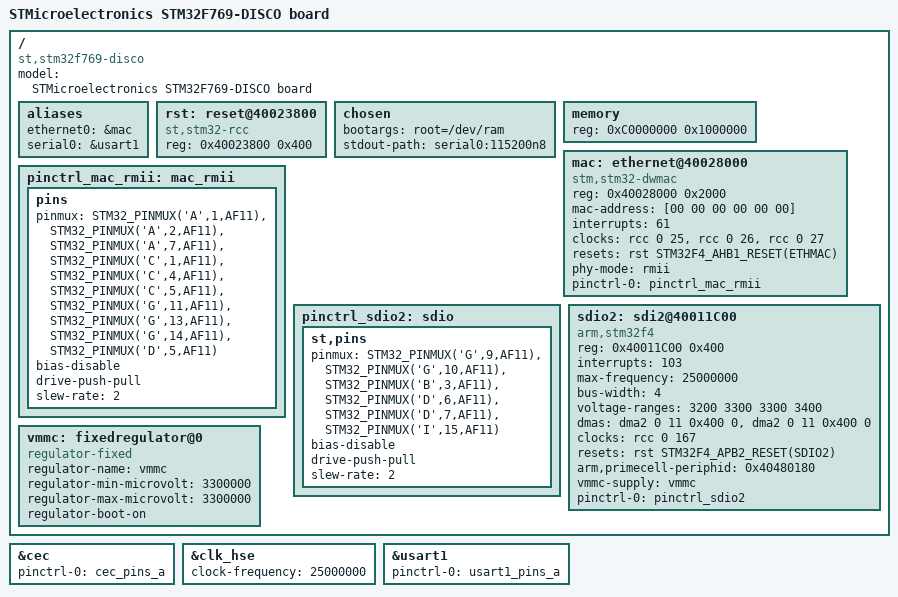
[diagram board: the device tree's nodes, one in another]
/*
 * Copyright 2017 - Vikas MANOCHA <vikas.manocha@st.com>
 *
 * This file is dual-licensed: you can use it either under the terms
 * of the GPL or the X11 license, at your option. Note that this dual
 * licensing only applies to this file, and not this project as a
 * whole.
 *
 *  a) This file is free software; you can redistribute it and/or
 *     modify it under the terms of the GNU General Public License as
 *     published by the Free Software Foundation; either version 2 of the
 *     License, or (at your option) any later version.
 *
 *     This file is distributed in the hope that it will be useful,
 *     but WITHOUT ANY WARRANTY; without even the implied warranty of
 *     MERCHANTABILITY or FITNESS FOR A PARTICULAR PURPOSE.  See the
 *     GNU General Public License for more details.
 *
 * Or, alternatively,
 *
 *  b) Permission is hereby granted, free of charge, to any person
 *     obtaining a copy of this software and associated documentation
 *     files (the "Software"), to deal in the Software without
 *     restriction, including without limitation the rights to use,
 *     copy, modify, merge, publish, distribute, sublicense, and/or
 *     sell copies of the Software, and to permit persons to whom the
 *     Software is furnished to do so, subject to the following
 *     conditions:
 *
 *     The above copyright notice and this permission notice shall be
 *     included in all copies or substantial portions of the Software.
 *
 *     THE SOFTWARE IS PROVIDED "AS IS", WITHOUT WARRANTY OF ANY KIND,
 *     EXPRESS OR IMPLIED, INCLUDING BUT NOT LIMITED TO THE WARRANTIES
 *     OF MERCHANTABILITY, FITNESS FOR A PARTICULAR PURPOSE AND
 *     NONINFRINGEMENT. IN NO EVENT SHALL THE AUTHORS OR COPYRIGHT
 *     HOLDERS BE LIABLE FOR ANY CLAIM, DAMAGES OR OTHER LIABILITY,
 *     WHETHER IN AN ACTION OF CONTRACT, TORT OR OTHERWISE, ARISING
 *     FROM, OUT OF OR IN CONNECTION WITH THE SOFTWARE OR THE USE OR
 *     OTHER DEALINGS IN THE SOFTWARE.
 */
 
 /* AHB1 */
#define STM32F4_RCC_AHB1_GPIOA	0
#define STM32F4_RCC_AHB1_GPIOB	1
#define STM32F4_RCC_AHB1_GPIOC	2
#define STM32F4_RCC_AHB1_GPIOD	3
#define STM32F4_RCC_AHB1_GPIOE	4
#define STM32F4_RCC_AHB1_GPIOF	5
#define STM32F4_RCC_AHB1_GPIOG	6
#define STM32F4_RCC_AHB1_GPIOH	7
#define STM32F4_RCC_AHB1_GPIOI	8
#define STM32F4_RCC_AHB1_GPIOJ	9
#define STM32F4_RCC_AHB1_GPIOK	10
#define STM32F4_RCC_AHB1_CRC	12
#define STM32F4_RCC_AHB1_DMA1	21
#define STM32F4_RCC_AHB1_DMA2	22
#define STM32F4_RCC_AHB1_DMA2D	23
#define STM32F4_RCC_AHB1_ETHMAC	25
#define STM32F4_RCC_AHB1_OTGHS	29

#define STM32F4_AHB1_RESET(bit) (STM32F4_RCC_AHB1_##bit + (0x10 * 8))

/* AHB2 */
#define STM32F4_RCC_AHB2_DCMI	0
#define STM32F4_RCC_AHB2_CRYP	4
#define STM32F4_RCC_AHB2_HASH	5
#define STM32F4_RCC_AHB2_RNG	6
#define STM32F4_RCC_AHB2_OTGFS	7

#define STM32F4_AHB2_RESET(bit)	(STM32F4_RCC_AHB2_##bit + (0x14 * 8))

/* AHB3 */
#define STM32F4_RCC_AHB3_FMC	0
#define STM32F4_RCC_AHB3_QSPI	1

#define STM32F4_AHB3_RESET(bit)	(STM32F4_RCC_AHB3_##bit + (0x18 * 8))

/* APB1 */
#define STM32F4_RCC_APB1_TIM2	0
#define STM32F4_RCC_APB1_TIM3	1
#define STM32F4_RCC_APB1_TIM4	2
#define STM32F4_RCC_APB1_TIM5	3
#define STM32F4_RCC_APB1_TIM6	4
#define STM32F4_RCC_APB1_TIM7	5
#define STM32F4_RCC_APB1_TIM12	6
#define STM32F4_RCC_APB1_TIM13	7
#define STM32F4_RCC_APB1_TIM14	8
#define STM32F4_RCC_APB1_WWDG	11
#define STM32F4_RCC_APB1_SPI2	14
#define STM32F4_RCC_APB1_SPI3	15
#define STM32F4_RCC_APB1_UART2	17
#define STM32F4_RCC_APB1_UART3	18
#define STM32F4_RCC_APB1_UART4	19
#define STM32F4_RCC_APB1_UART5	20
#define STM32F4_RCC_APB1_I2C1	21
#define STM32F4_RCC_APB1_I2C2	22
#define STM32F4_RCC_APB1_I2C3	23
#define STM32F4_RCC_APB1_I2C4	24
#define STM32F4_RCC_APB1_CAN1	25
#define STM32F4_RCC_APB1_CAN2	26
#define STM32F4_RCC_APB1_PWR	28
#define STM32F4_RCC_APB1_DAC	29
#define STM32F4_RCC_APB1_UART7	30
#define STM32F4_RCC_APB1_UART8	31

#define STM32F4_APB1_RESET(bit)	(STM32F4_RCC_APB1_##bit + (0x20 * 8))

/* APB2 */
#define STM32F4_RCC_APB2_TIM1	0
#define STM32F4_RCC_APB2_TIM8	1
#define STM32F4_RCC_APB2_USART1	4
#define STM32F4_RCC_APB2_USART6	5
#define STM32F4_RCC_APB2_SDIO2	7
#define STM32F4_RCC_APB2_ADC	8
#define STM32F4_RCC_APB2_SDIO	11
#define STM32F4_RCC_APB2_SPI1	12
#define STM32F4_RCC_APB2_SPI4	13
#define STM32F4_RCC_APB2_SYSCFG	14
#define STM32F4_RCC_APB2_TIM9	16
#define STM32F4_RCC_APB2_TIM10	17
#define STM32F4_RCC_APB2_TIM11	18
#define STM32F4_RCC_APB2_SPI5	20
#define STM32F4_RCC_APB2_SPI6	21
#define STM32F4_RCC_APB2_SAI1	22
#define STM32F4_RCC_APB2_SAI2	23
#define STM32F4_RCC_APB2_LTDC	26
#define STM32F4_RCC_APB2_DSI	27

#define STM32F4_APB2_RESET(bit)	(STM32F4_RCC_APB2_##bit + (0x24 * 8))



/dts-v1/;
#include "stm32f746.dtsi"
#include <dt-bindings/input/input.h>

/ {
	model = "STMicroelectronics STM32F769-DISCO board";
	compatible = "st,stm32f769-disco", "st,stm32f7";
	
	aliases {
        ethernet0 = &mac;
        
    };
    
    rst: reset@40023800 {
        #reset-cells = <1>;
        compatible = "st,stm32-rcc";
        reg = <0x40023800 0x400>;
    };
	
	chosen {
		bootargs = "root=/dev/ram";
		stdout-path = "serial0:115200n8";
	};

	memory {
		reg = <0xC0000000 0x1000000>;
	};

	aliases {
		serial0 = &usart1;
	};
	
	
    mac: ethernet@40028000 {
        compatible = "stm,stm32-dwmac", "snps,dwmac-3.611",
                    "snps,dwmac";
        reg = <0x40028000 0x2000>;
        //MAC is filled in by U-Boot
        mac-address = [00 00 00 00 00 00];
        interrupts = <61>;
        interrupt-names = "macirq";
        clocks = <&rcc 0 25>, <&rcc 0 26>, <&rcc 0 27>;
        clock-names = "stmmaceth", "stm32_mac_tx","stm32_mac_rx";
        resets = <&rst STM32F4_AHB1_RESET(ETHMAC)>;
        reset-names = "stmmaceth";
        status = "enable";
    };
    
	
    pinctrl_mac_rmii: mac_rmii {
        pins {
            pinmux =  <STM32_PINMUX('A',1,AF11)>,   // ref_clk
                        <STM32_PINMUX('A',2,AF11)>,   // mdio 
                        <STM32_PINMUX('A',7,AF11)>, // crs_dv
                        <STM32_PINMUX('C',1,AF11)>, // mcd
                        <STM32_PINMUX('C',4,AF11)>, // rxd0
                        <STM32_PINMUX('C',5,AF11)>, // rxd1
                        <STM32_PINMUX('G',11,AF11)>, // tx_en
                        <STM32_PINMUX('G',13,AF11)>, // txd0
                        <STM32_PINMUX('G',14,AF11)>, // txd1
                        
                        <STM32_PINMUX('D',5,AF11)>; // rx_er
                        
                        bias-disable;
                        drive-push-pull;
                        slew-rate = <2>;
                };
        };
        
    pinctrl_sdio2: sdio {
    st,pins {
        
        pinmux = <STM32_PINMUX('G',9,AF11)>,    //d0
                <STM32_PINMUX('G',10,AF11)>,    //d1
                <STM32_PINMUX('B',3,AF11)>,    //d2
                <STM32_PINMUX('D',6,AF11)>,    //ck
                <STM32_PINMUX('D',7,AF11)>,    //cmd
                <STM32_PINMUX('I',15,AF11)>;    //cd
             
                bias-disable;
                drive-push-pull;
                slew-rate = <2>;           
            };
    };
    
    sdio2: sdi2@40011C00 {
        compatible = "arm,stm32f4", "arm,primecell";
        reg = <0x40011C00 0x400>;
        interrupts = <103>;
        max-frequency = <25000000>;
        bus-width = <4>;
        voltage-ranges = <3200 3300 3300 3400>;
        /* Use the same DMA both for rx and tx */
        dmas = <&dma2 0 11 0x400 0>, <&dma2 0 11 0x400 0>;
        dma-names = "rx", "tx";
        clocks = <&rcc 0 167>;
        clock-names = "apb_pclk";
        resets = <&rst STM32F4_APB2_RESET(SDIO2)>;
        arm,primecell-periphid = <0x40480180>;
        vmmc-supply = <&vmmc>;
        status = "disabled";
    };

    vmmc: fixedregulator@0 {
		compatible = "regulator-fixed";
		regulator-name = "vmmc";
		regulator-min-microvolt = <3300000>;
		regulator-max-microvolt = <3300000>;
		regulator-boot-on;
	};

	


};

/*
 * Ethernet controller
 */
&mac {
	status = "okay";
	phy-mode = "rmii";
	pinctrl-names = "default";
	pinctrl-0 = <&pinctrl_mac_rmii>;
};

&cec {
	pinctrl-0 = <&cec_pins_a>;
	pinctrl-names = "default";
	status = "okay";
};

&clk_hse {
	clock-frequency = <25000000>;
};

&usart1 {
	pinctrl-0 = <&usart1_pins_a>;
	pinctrl-names = "default";
	status = "okay";
};

&sdio2 {
	status = "okay";
	pinctrl-names = "default";
	pinctrl-0 = <&pinctrl_sdio2>;
	//cd-gpio = <&gpioi 15 GPIO_ACTIVE_LOW>;
};
